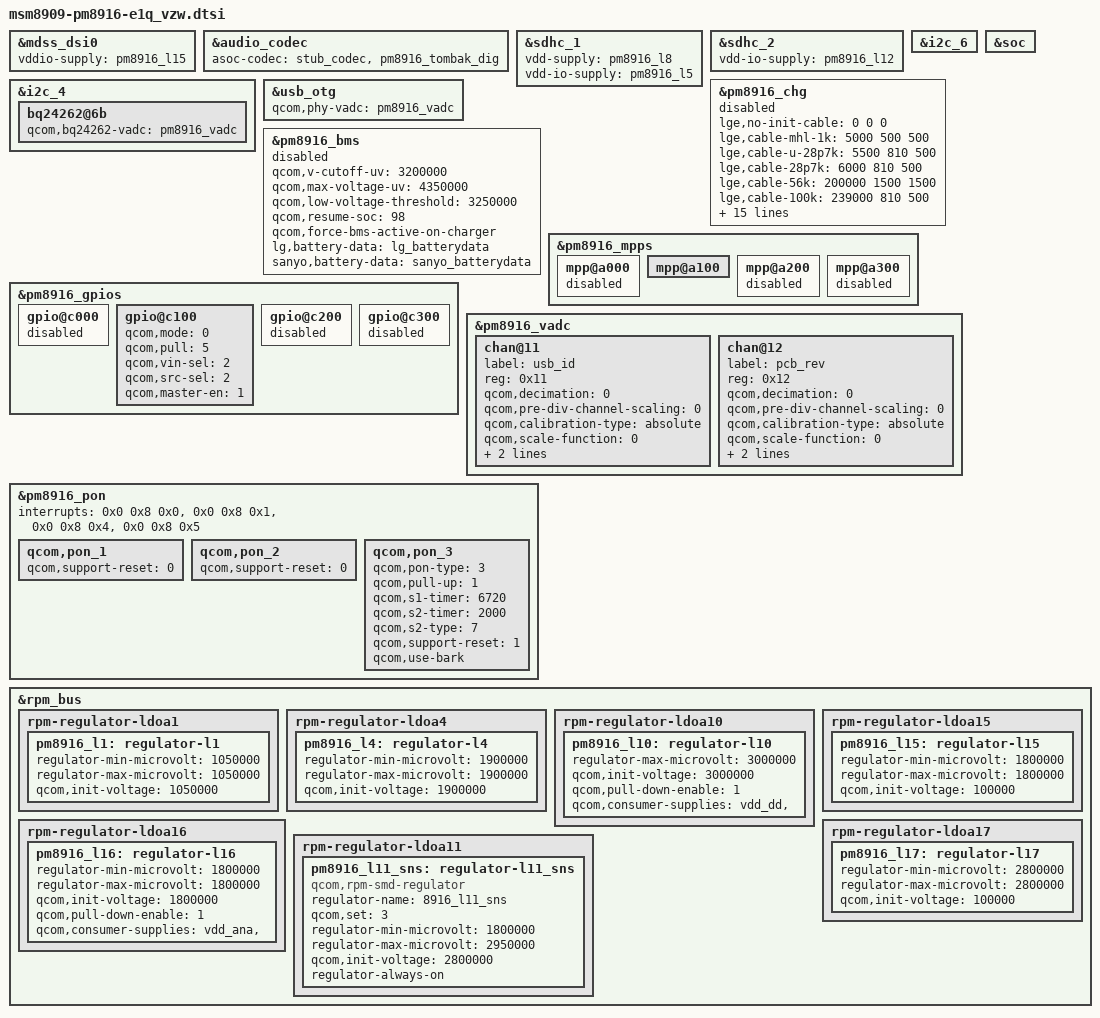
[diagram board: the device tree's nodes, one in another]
/* Copyright (c) 2014, The Linux Foundation. All rights reserved.
 *
 * This program is free software; you can redistribute it and/or modify
 * it under the terms of the GNU General Public License version 2 and
 * only version 2 as published by the Free Software Foundation.
 *
 * This program is distributed in the hope that it will be useful,
 * but WITHOUT ANY WARRANTY; without even the implied warranty of
 * MERCHANTABILITY or FITNESS FOR A PARTICULAR PURPOSE.  See the
 * GNU General Public License for more details.
 */

#include "pm8916-vibrator.dtsi"
#include "pm8916-led.dtsi"

&mdss_dsi0 {
	vddio-supply = <&pm8916_l15>;
};

&audio_codec {
	asoc-codec = <&stub_codec>, <&pm8916_tombak_dig>;
};

&sdhc_1 {
	vdd-supply = <&pm8916_l8>;
	vdd-io-supply = <&pm8916_l5>;
};

&sdhc_2 {
	vdd-io-supply = <&pm8916_l12>;
};

/*&i2c_1 {
	rpr05210@38 {
		Avago,vdd_ana-supply = <&pm8916_l11>;
		Avago,vddio_i2c-supply = <&pm8916_l6>;
	};

	st_k303b_acc@1d {
		Bosch,vdd_ana-supply = <&pm8916_l11>;
		Bosch,vddio_i2c-supply = <&pm8916_l6>;
	};

	st_k303b_mag@1e {
		Bosch,vdd_ana-supply = <&pm8916_l11>;
		Bosch,vddio_i2c-supply = <&pm8916_l6>;
	};

};*/

&i2c_4 {
	bq24262@6b {
		qcom,bq24262-vadc = <&pm8916_vadc>;
	};
};

&i2c_6 {
};

&usb_otg {
	qcom,phy-vadc = <&pm8916_vadc>;
};

&pm8916_chg {
	status = "disabled";

	lge,no-init-cable = <0 0 0>;
	lge,cable-mhl-1k = <5000 500 500>;
	lge,cable-u-28p7k = <5500 810 500>;
	lge,cable-28p7k = <6000 810 500>;
	lge,cable-56k = <200000 1500 1500>;
	lge,cable-100k = <239000 810 500>;
	lge,cable-130k = <340000 1500 1500>;
	lge,cable-180k = <400000 810 500>;
	lge,cable-200k = <410000 810 500>;
	lge,cable-220k = <485000 810 500>;
	lge,cable-270k = <560000 810 500>;
	lge,cable-330k = <735000 810 500>;
	lge,cable-620k = <955000 810 500>;
	lge,cable-910k = <1140000 1500 1500>;
	lge,cable-none = <1900000 810  500>;

	qcom,vddmax-mv = <4350>;
	qcom,vddsafe-mv = <4380>;
	qcom,vinmin-mv = <4470>;
	qcom,tchg-mins = <480>;
	qcom,btc-disabled;
	qcom,disable-vbatdet-based-recharge;
	/delete-property/ qcom,thermal-mitigation;
	/delete-property/ qcom,cool-bat-decidegc;
	/delete-property/ qcom,warm-bat-decidegc;
};

&pm8916_bms {
	status = "disabled";
	qcom,v-cutoff-uv = <3200000>;
	qcom,max-voltage-uv = <4350000>;
	qcom,low-voltage-threshold = <3250000>;
	qcom,resume-soc = <98>;
	qcom,force-bms-active-on-charger;
	lg,battery-data = <&lg_batterydata>;
	sanyo,battery-data = <&sanyo_batterydata>;
};

&pm8916_mpps {
	mpp@a000 { /* MPP 1 */
		/* VDD_PX */
		status = "disabled";
	};

	mpp@a100 { /* MPP 2 */
		/* Backlight PWM */
		status = "ok";
	};

	mpp@a200 { /* MPP 3 */
		/* VREF DAC */
		status = "disabled";
	};

	mpp@a300 { /* MPP 4 */
		/* HR LED */
		status = "disabled";
	};
};

&pm8916_gpios {
	gpio@c000 { /* GPIO 1 */
		/* Battery UICC Alarm */
		status = "disabled";
	};

	gpio@c100 { /* GPIO 2 */
		/* NFC_CLK_REQ */
		qcom,mode = <0>; /* QPNP_PIN_MODE_DIG_IN */
		qcom,pull = <5>; /* QPNP_PIN_PULL_NO */
		qcom,vin-sel = <2>; /* QPNP_PIN_VIN2 */
		qcom,src-sel = <2>; /* QPNP_PIN_SEL_FUNC_1 */
		qcom,master-en = <1>;
	};

	gpio@c200 { /* GPIO 3 */
		/* External regulator control for WTR */
		status = "disabled";
	};

	gpio@c300 { /* GPIO 4 */
		/* External regulator control for APC */
		status = "disabled";
	};
};

&pm8916_vadc {
	chan@11 {
		label = "usb_id";
		reg = <0x11>;
		qcom,decimation = <0>;
		qcom,pre-div-channel-scaling = <0>;
		qcom,calibration-type = "absolute";
		qcom,scale-function = <0>;
		qcom,hw-settle-time = <2>;
		qcom,fast-avg-setup = <0>;
	};

	chan@12 {
		label = "pcb_rev";
		reg = <0x12>;
		qcom,decimation = <0>;
		qcom,pre-div-channel-scaling = <0>;
		qcom,calibration-type = "absolute";
		qcom,scale-function = <0>;
		qcom,hw-settle-time = <0xb>;
		qcom,fast-avg-setup = <0>;
	};
};

&pm8916_pon {
	status = "ok";
	interrupts = <0x0 0x8 0x0>,
		     <0x0 0x8 0x1>,
		     <0x0 0x8 0x4>,
		     <0x0 0x8 0x5>;
	interrupt-names = "kpdpwr", "resin",
		"resin-bark", "kpdpwr-resin-bark";

	qcom,pon_1 {
		status = "ok";
		qcom,support-reset = <0>;
	};
	qcom,pon_2 {
		status = "ok";
		qcom,support-reset = <0>;
	};
	qcom,pon_3 {
		status = "ok";
		qcom,pon-type = <3>;
		qcom,pull-up = <1>;
		qcom,s1-timer = <6720>;
		qcom,s2-timer = <2000>;
		qcom,s2-type = <7>;
		qcom,support-reset = <1>;
		qcom,use-bark;
	};
};

&soc {
};

/* RPM controlled regulators */
&rpm_bus {
	/* WTR */
	rpm-regulator-ldoa1 {
		status = "okay";
		pm8916_l1: regulator-l1 {
			status = "okay";
			regulator-min-microvolt = <1050000>;
			regulator-max-microvolt = <1050000>;
			qcom,init-voltage = <1050000>;
		};
	};

	rpm-regulator-ldoa4 {
		status = "okay";
		pm8916_l4: regulator-l4 {
			status = "okay";
			regulator-min-microvolt = <1900000>;
			regulator-max-microvolt = <1900000>;
			qcom,init-voltage = <1900000>;
		};
	};
	
	/* Touch VDD 3.0V */
	rpm-regulator-ldoa10 {
		status = "okay";
		pm8916_l10: regulator-l10 {
			regulator-max-microvolt = <3000000>;
			qcom,init-voltage = <3000000>;
			qcom,pull-down-enable = <1>;
			qcom,consumer-supplies = "vdd_dd", "";
			status = "okay";
		};
	};
	/* Touch VIO 1.8V */
	rpm-regulator-ldoa16 {
		status = "okay";
		pm8916_l16: regulator-l16 {
			regulator-min-microvolt = <1800000>;
			regulator-max-microvolt = <1800000>;
			qcom,init-voltage = <1800000>;
			qcom,pull-down-enable = <1>;
			qcom,consumer-supplies = "vdd_ana", "";
			status = "okay";
		};
	};

	rpm-regulator-ldoa11 {
		status = "ok";
		pm8916_l11_sns: regulator-l11_sns {
			status = "ok";
			compatible = "qcom,rpm-smd-regulator";
			regulator-name = "8916_l11_sns";
			qcom,set = <3>;
			regulator-min-microvolt = <1800000>;
			regulator-max-microvolt = <2950000>;
			qcom,init-voltage = <2800000>;
			regulator-always-on;
			};
	};

	/* regulator settings for LCD VDDIO */
	rpm-regulator-ldoa15 {
		status = "okay";
		pm8916_l15: regulator-l15 {
			regulator-min-microvolt = <1800000>;
			regulator-max-microvolt = <1800000>;
			qcom,init-voltage       = <100000>;
			status = "okay";
		};
	};
	rpm-regulator-ldoa17 {
		status = "okay";
		pm8916_l17: regulator-l17 {
			regulator-min-microvolt = <2800000>;
			regulator-max-microvolt = <2800000>;
			qcom,init-voltage       = <100000>;
			status = "okay";
		};
	};
};
